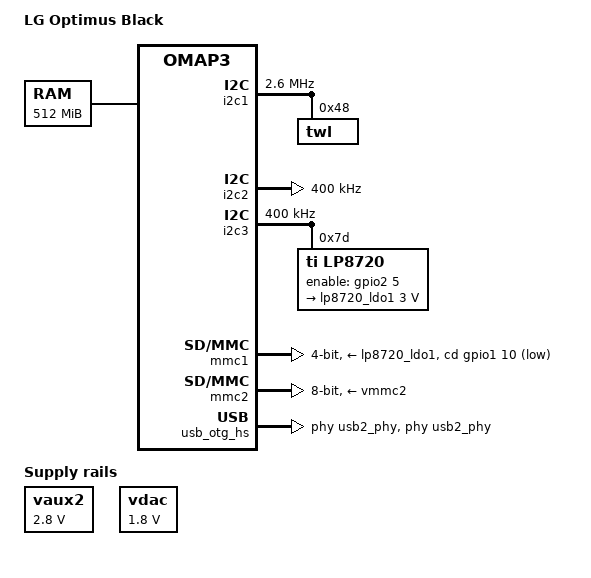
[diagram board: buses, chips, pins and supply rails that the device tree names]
/dts-v1/;
#include "omap36xx.dtsi"
#include <dt-bindings/input/input.h>
/ {
	model = "LG Optimus Black";
	compatible = "lg,omap3-sniper", "ti,omap3630", "ti,omap3";
	cpus {
		cpu@0 {
			cpu0-supply = <&vcc>;
		};
	};
	memory@80000000 {
		device_type = "memory";
		reg = <0x80000000 0x20000000>;  
	};
};
&omap3_pmx_core {
	pinctrl-names = "default";
	uart3_pins: uart3-pins {
		pinctrl-single,pins = <
			OMAP3_CORE1_IOPAD(0x219e, PIN_INPUT | MUX_MODE0)	 
			OMAP3_CORE1_IOPAD(0x21a0, PIN_OUTPUT | MUX_MODE0)	 
		>;
	};
	dp3t_sel_pins: dp3t-sel-pins {
		pinctrl-single,pins = <
			OMAP3_CORE1_IOPAD(0x2196, PIN_OUTPUT | MUX_MODE4)	 
			OMAP3_CORE1_IOPAD(0x2198, PIN_OUTPUT | MUX_MODE4)	 
		>;
	};
	i2c1_pins: i2c1-pins {
		pinctrl-single,pins = <
			OMAP3_CORE1_IOPAD(0x21ba, PIN_INPUT | MUX_MODE0)	 
			OMAP3_CORE1_IOPAD(0x21bc, PIN_INPUT | MUX_MODE0)	 
		>;
	};
	i2c2_pins: i2c2-pins {
		pinctrl-single,pins = <
			OMAP3_CORE1_IOPAD(0x21be, PIN_INPUT | MUX_MODE0)	 
			OMAP3_CORE1_IOPAD(0x21c0, PIN_INPUT | MUX_MODE0)	 
		>;
	};
	i2c3_pins: i2c3-pins {
		pinctrl-single,pins = <
			OMAP3_CORE1_IOPAD(0x21c2, PIN_INPUT | MUX_MODE0)	 
			OMAP3_CORE1_IOPAD(0x21c4, PIN_INPUT | MUX_MODE0)	 
		>;
	};
	lp8720_en_pin: lp8720-en-pins {
		pinctrl-single,pins = <
			OMAP3_CORE1_IOPAD(0x2080, PIN_OUTPUT | MUX_MODE4)	 
		>;
	};
	mmc1_pins: mmc1-pins {
		pinctrl-single,pins = <
			OMAP3_CORE1_IOPAD(0x2144, PIN_INPUT | MUX_MODE0)	 
			OMAP3_CORE1_IOPAD(0x2146, PIN_INPUT | MUX_MODE0)	 
			OMAP3_CORE1_IOPAD(0x2148, PIN_INPUT | MUX_MODE0)	 
			OMAP3_CORE1_IOPAD(0x214a, PIN_INPUT | MUX_MODE0)	 
			OMAP3_CORE1_IOPAD(0x214c, PIN_INPUT | MUX_MODE0)	 
			OMAP3_CORE1_IOPAD(0x214e, PIN_INPUT | MUX_MODE0)	 
		>;
	};
	mmc2_pins: mmc2-pins {
		pinctrl-single,pins = <
			OMAP3_CORE1_IOPAD(0x2158, PIN_INPUT | MUX_MODE0)	 
			OMAP3_CORE1_IOPAD(0x215a, PIN_INPUT | MUX_MODE0)	 
			OMAP3_CORE1_IOPAD(0x215c, PIN_INPUT | MUX_MODE0)	 
			OMAP3_CORE1_IOPAD(0x215e, PIN_INPUT | MUX_MODE0)	 
			OMAP3_CORE1_IOPAD(0x2160, PIN_INPUT | MUX_MODE0)	 
			OMAP3_CORE1_IOPAD(0x2162, PIN_INPUT | MUX_MODE0)	 
			OMAP3_CORE1_IOPAD(0x2164, PIN_INPUT | MUX_MODE0)	 
			OMAP3_CORE1_IOPAD(0x2166, PIN_INPUT | MUX_MODE0)	 
			OMAP3_CORE1_IOPAD(0x2168, PIN_INPUT | MUX_MODE0)	 
			OMAP3_CORE1_IOPAD(0x216a, PIN_INPUT | MUX_MODE0)	 
		>;
	};
	usb_otg_hs_pins: usb-otg-hs-pins {
		pinctrl-single,pins = <
			OMAP3_CORE1_IOPAD(0x21a2, PIN_INPUT | MUX_MODE0)	 
			OMAP3_CORE1_IOPAD(0x21a4, PIN_OUTPUT | MUX_MODE0)	 
			OMAP3_CORE1_IOPAD(0x21a6, PIN_INPUT | MUX_MODE0)	 
			OMAP3_CORE1_IOPAD(0x21a8, PIN_INPUT | MUX_MODE0)	 
			OMAP3_CORE1_IOPAD(0x21aa, PIN_INPUT | MUX_MODE0)	 
			OMAP3_CORE1_IOPAD(0x21ac, PIN_INPUT | MUX_MODE0)	 
			OMAP3_CORE1_IOPAD(0x21ae, PIN_INPUT | MUX_MODE0)	 
			OMAP3_CORE1_IOPAD(0x21b0, PIN_INPUT | MUX_MODE0)	 
			OMAP3_CORE1_IOPAD(0x21b2, PIN_INPUT | MUX_MODE0)	 
			OMAP3_CORE1_IOPAD(0x21b4, PIN_INPUT | MUX_MODE0)	 
			OMAP3_CORE1_IOPAD(0x21b6, PIN_INPUT | MUX_MODE0)	 
			OMAP3_CORE1_IOPAD(0x21b8, PIN_INPUT | MUX_MODE0)	 
		>;
	};
};
&omap3_pmx_wkup {
	pinctrl-names = "default";
	mmc1_cd_pin: mmc1-cd-pins {
		pinctrl-single,pins = <
			OMAP3_WKUP_IOPAD(0x2a1a, PIN_INPUT | MUX_MODE4)		 
		>;
	};
};
&gpio2 {
	ti,no-reset-on-init;
};
&gpio5 {
	ti,no-reset-on-init;
};
&gpio6 {
	ti,no-reset-on-init;
};
&uart3 {
	pinctrl-names = "default";
	pinctrl-0 = <&uart3_pins &dp3t_sel_pins>;
	interrupts-extended = <&intc 74 &omap3_pmx_core OMAP3_UART3_RX>;
};
&i2c1 {
	pinctrl-names = "default";
	pinctrl-0 = <&i2c1_pins>;
	clock-frequency = <2600000>;
	twl: twl@48 {
		reg = <0x48>;
		interrupts = <7>;  
		interrupt-parent = <&intc>;
		power {
			compatible = "ti,twl4030-power";
			ti,use_poweroff;
		};
	};
};
&i2c2 {
	pinctrl-names = "default";
	pinctrl-0 = <&i2c2_pins>;
	clock-frequency = <400000>;
};
&i2c3 {
	pinctrl-names = "default";
	pinctrl-0 = <&i2c3_pins>;
	clock-frequency = <400000>;
	lp8720@7d {
		pinctrl-names = "default";
		pinctrl-0 = <&lp8720_en_pin>;
		compatible = "ti,lp8720";
		reg = <0x7d>;
		enable-gpios = <&gpio2 5 GPIO_ACTIVE_HIGH>;  
		lp8720_ldo1: ldo1 {
			regulator-min-microvolt = <3000000>;
			regulator-max-microvolt = <3000000>;
		};
	};
};
&mmc1 {
	pinctrl-names = "default";
	pinctrl-0 = <&mmc1_pins &mmc1_cd_pin>;
	vmmc-supply = <&lp8720_ldo1>;
	cd-gpios = <&gpio1 10 GPIO_ACTIVE_LOW>;  
	bus-width = <4>;
};
&mmc2 {
	pinctrl-names = "default";
	pinctrl-0 = <&mmc2_pins>;
	vmmc-supply = <&vmmc2>;
	ti,non-removable;
	bus-width = <8>;
};
&mmc3 {
	status = "disabled";
};
&usb_otg_hs {
	pinctrl-names = "default";
	pinctrl-0 = <&usb_otg_hs_pins>;
	interface-type = <0>;
	usb-phy = <&usb2_phy>;
	phys = <&usb2_phy>;
	phy-names = "usb2-phy";
	mode = <3>;
	power = <50>;
};
#include "twl4030.dtsi"
#include "twl4030_omap3.dtsi"
&twl_keypad {
	linux,keymap = <
		MATRIX_KEY(0x00, 0x00, KEY_VOLUMEUP)
		MATRIX_KEY(0x01, 0x00, KEY_VOLUMEDOWN)
		MATRIX_KEY(0x02, 0x00, KEY_SELECT)
	>;
};
&vaux2 {
	regulator-min-microvolt = <2800000>;
	regulator-max-microvolt = <2800000>;
	regulator-always-on;
};
&vdac {
	regulator-min-microvolt = <1800000>;
	regulator-max-microvolt = <1800000>;
	regulator-always-on;
};
